# emac_reva register map
Registers are read-write, no defined reset value unless marked. A register's access mark holds for its fields unless they carry their own. Offsets are from the block's base; lines under a group give offsets from that group; [hi:lo] are bit positions; {n}, {i} and the like mark numbered series; 'fields as' and 'values as' point back to an identical list; <NAME> marks a mode.

## Memory map
0x4004F000 EMAC size 0x1000 — 10/100 Ethernet MAC.

## Interrupts
64 EMAC — EMAC IRQ

## EMAC — 10/100 Ethernet MAC.
Base 0x4004F000
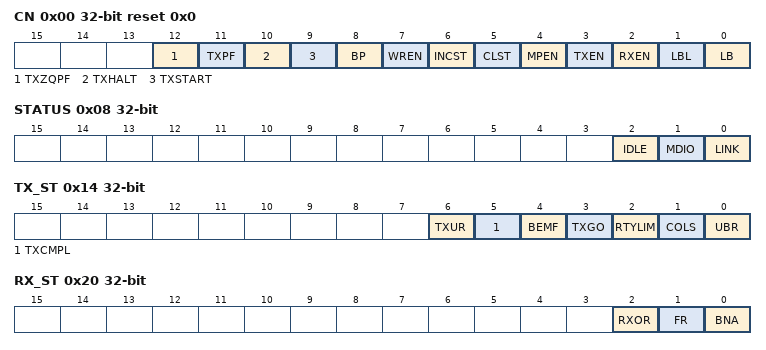
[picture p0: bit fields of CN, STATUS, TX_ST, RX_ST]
0x00 CN access per field reset 0x0 — Network Control Register.
  [12] TXZQPF wo — Transmit zero quantum pause frame.
  [11] TXPF wo — Transmit pause frame.
  [10] TXHALT wo — Transmit halt.
  [9] TXSTART wo — Transmission start.
  [8] BP rw — Back pressure.
  [7] WREN rw — Write enable for statistics registers.
  [6] INCST wo — Increment Statistics.
  [5] CLST wo — Clear Statistics.
  [4] MPEN rw — Management Port Enable.
  [3] TXEN rw — Transmit Enable.
  [2] RXEN rw — Receive Enable.
  [1] LBL rw — Loopback local.
  [0] LB rw — Loopback.
0x04 CFG access per field — Network Configuration Register.
  [19] IGNRXFCS wo — Ignore RX FCS. If 1, packets with FCS/CRC errors are not rejected and no FCS error statistics are counted. For normal operation, this bit must be set to 0.
  [18] HDPLXRXEN wo — Enable packets to be received in half-duplex mode while transmitting.
  [17] DCRXFCS wo — Discard receive FCS. If 1, the FCS field of received frames will not be copied to memory.
  [16] RXLFCEN wo — Receive length field checking enable. If 1, packets with measured lengths shorter than their length fields are discarded. Packets containing a type ID in bytes 13 and 14 (length/type field ≥0600) are not counted as length errors.
  [15:14] RXBUFFOFS wo — Receive buffer offset. These bits indicate the number of bytes by which the received data is offset from the start of the first receive buffer.
  [13] PAUSEEN wo — Pause Enable. If 1, Ethernet packet transmission pauses when a valid pause packet is received.
  [12] RTTST wo — Retry Test. Must be set to zero for normal operation. If set to 1, the back-off between collisions is always one slot time.
  [11] TXPF wo — Transmit pause frame.
  [11:10] MDCCLK wo — MDC Frequency. Set according to PCLK speed. This field determines by what number PCLK is divided to generate MDC.
    0=div8 (PCLK up to 20MHz); 1=div16 (PCLK up to 40MHz); 2=div32 (PCLK up to 80MHz); 3=div64 (PCLK up to 160MHz)
  [9] EAE rw
  [8] RXFR rw — Receive 1536 Byte Frames. Writing 1 to this bit means the MAC receives packets up to 1536 bytes in length. Normally the MAC rejects any packet above 1518 bytes
  [7] UHEN rw — Unicast Hash Enable. If 1, unicast frames will be received when the 6 bit hash function of the destination address points to a bit that is set in the hash register.
  [6] MHEN wo — Multicast Hash Enable. If 1, multicast frames will be received when the 6 bit hash function of the destination address points to a bit that is set in the hash register.
  [5] NOBC wo — No Broadcast. If 1, frames addressed to the broadcast address of all ones will not be received.
  [4] COPYAF rw — Copy All Frames. If 1, all valid frames will be received.
  [3] JUMBOFR rw — Jumbo Frames. Writing 1 to this bit enables jumbo frames of up to 10,240 bytes to be accepted.
  [2] BITRATE rw — Bit Rate. Writing 1 to this bit configures the interface for serial operation.
  [1] FULLDPLX rw — Full Duplex. If set to 1 the transmit block ignores the state of collision and carrier sense and allows Rx while transmitting.
  [0] SPD rw — Speed Select.
0x08 STATUS ro — Network Status Register.
  [2] IDLE rw — PHY management logic status.
  [1] MDIO rw — MDIO pin status. Returns status of the EMAC_MDIO pin. Use the PHY maintenance register for reading managed frames rather than this bit.
  [0] LINK rw — LINK pin status. Returns status of EMAC_LINK pin.
0x14 TX_ST — Transmit Status Register.
  [6] TXUR — Transmit Underrun. Set when the MAC transmit FIFO was read while was empty. If this happens the transmitter forces bad. Write 1 to clear this bit.
  [5] TXCMPL — Transmit Complete. Set when a frame has been transmitted. Write 1 to clear this bit.
  [4] BEMF — Buffers Exhausted Mid Frame. If the buffers run out during transmission of a frame then transmission stops, FCS shall be bad and EMAC_TXER asserted. Write 1 to clear this bit.
  [3] TXGO — Transmit Go. If 1, transmit is active.
  [2] RTYLIM — Retry Limit Exceeded. Set when the retry limit has been exceeded. Write 1 to clear this bit.
  [1] COLS — Collision Occurred. Set when a collision occurs. Write 1 to clear this bit.
  [0] UBR — Used Bit Read. Set when a transmit buffer descriptor is read with its used bit set. Write 1 to clear this bit.
0x18 RXBUF_PTR — Receive Buffer Queue Pointer Register.
  [31:2] RXBUF — Receive buffer queue pointer. Written with the address of the start of the receive queue, reads as a pointer to the current buffer being used.
0x1C TXBUF_PTR — Transmit Buffer Queue Pointer Register.
  [31:2] TXBUF — Transmit buffer queue pointer. Written with the address of the start of the transmit queue, reads as a pointer to the first buffer of the frame being transmitted or about to be transmitted.
0x20 RX_ST — Receive Status Register.
  [2] RXOR — Receive Overrun. The DMA block was unable to store the receive frame to memory. Either because the AHB bus was not granted in time or because a not OK hresp was returned. The buffer will be recovered if this happens. Write 1 to clear this bit.
  [1] FR — Frame Received. One or more frames have been received and placed in memory. Write 1 to clear this bit.
  [0] BNA — Buffer Not Available. An attempt was made to get a new buffer and the pointer indicated that it was owned by the processor. The DMA will reread the pointer each time a new frame starts until a valid pointer is found. This bit will be set at each attempt that fails even if it has not had a successful pointer read since it has been cleared. Write 1 to clear this bit.
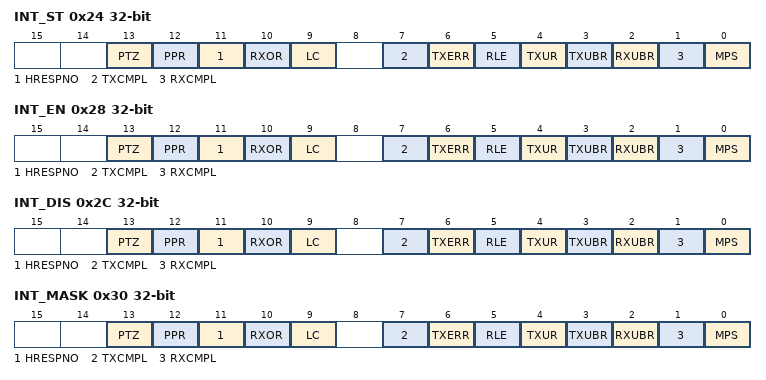
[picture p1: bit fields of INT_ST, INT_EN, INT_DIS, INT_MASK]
0x24 INT_ST — Interrupt Status Register.
  [13] PTZ — Pause Time Zero Interrupt Status. Set when the MAC Pause Time register (MAC_PT) decrements to zero. Cleared when read.
  [12] PPR — Pause Packet Received Interrupt Status. Indicates a valid pause packet has been received. Cleared when read.
  [11] HRESPNO — hresp not OK Interrupt Status. Set when the DMA block sees hresp not OK. Cleared when read.
  [10] RXOR — Receive Overrun Interrupt Status. Set when the receive overrun status bit gets set. Cleared when read.
  [9] LC — Link Change Interrupt Status. Set when the external link signal changes. Cleared when read.
  [7] TXCMPL — Transmit Complete Interrupt Status. Set when a frame has been transmitted. Cleared when read.
  [6] TXERR — Transmit Buffers Exhausted In Mid-frame Interrupt Status. Transmit error. Cleared when read.
  [5] RLE — Retry Limit Exceeded Interrupt Status. Transmit error. Cleared when read.
  [4] TXUR — Ethernet Transmit Underrun Interrupt Status. Set when the MAC transmit FIFO was read while was empty. If this happens the transmitter forces bad CRC and forces EMAC_TXER high. Cleared when read.
  [3] TXUBR — TX Used Bit Read Interrupt Status. Set when a transmit buffer descriptor is read with its used bit set. Cleared when read
  [2] RXUBR — RX Used Bit Read Interrupt Status. Set when a receive buffer descriptor is read with its used bit set. Cleared when read.
  [1] RXCMPL — Receive Complete Interrupt Status. Set when a frame has been stored in memory. Cleared when read.
  [0] MPS — Management Packet Sent Interrupt Status. The PHY maintenance register has completed its operation. Cleared when read.
0x28 INT_EN wo — Interrupt Enable Register.
  [13] PTZ rw — Pause Time Zero Interrupt Enable
  [12] PPR rw — Pause Packet Received Interrupt Enable
  [11] HRESPNO rw — hresp not OK Interrupt Enable
  [10] RXOR rw — Receive Overrun Interrupt Enable
  [9] LC rw — Link Change Interrupt Enable
  [7] TXCMPL rw — Transmit Complete Interrupt Enable
  [6] TXERR rw — Transmit Buffers Exhausted In Mid-frame Interrupt Enable
  [5] RLE rw — Retry Limit Exceeded Interrupt Enable
  [4] TXUR rw — Ethernet Transmit Underrun Interrupt Enable
  [3] TXUBR rw — TX Used Bit Read Interrupt Enable
  [2] RXUBR rw — RX Used Bit Read Interrupt Enable
  [1] RXCMPL rw — Receive Complete Interrupt Enable
  [0] MPS rw — Management Packet Sent Interrupt Enable
0x2C INT_DIS wo — Interrupt Disable Register.
  [13] PTZ rw — Pause Time Zero Interrupt Disable
  [12] PPR rw — Pause Packet Received Interrupt Disable
  [11] HRESPNO rw — hresp not OK Interrupt Disable
  [10] RXOR rw — Receive Overrun Interrupt Disable
  [9] LC rw — Link Change Interrupt Disable
  [7] TXCMPL rw — Transmit Complete Interrupt Disable
  [6] TXERR rw — Transmit Buffers Exhausted In Mid-frame Interrupt Disable
  [5] RLE rw — Retry Limit Exceeded Interrupt Disable
  [4] TXUR rw — Ethernet Transmit Underrun Interrupt Disable
  [3] TXUBR rw — TX Used Bit Read Interrupt Disable
  [2] RXUBR rw — RX Used Bit Read Interrupt Disable
  [1] RXCMPL rw — Receive Complete Interrupt Disable
  [0] MPS rw — Management Packet Sent Interrupt Disable
0x30 INT_MASK ro — Interrupt Mask Register.
  [13] PTZ rw — Pause Time Zero Interrupt Mask
  [12] PPR rw — Pause Packet Received Interrupt Mask
  [11] HRESPNO rw — hresp not OK Interrupt Mask
  [10] RXOR rw — Receive Overrun Interrupt Mask
  [9] LC rw — Link Change Interrupt Mask
  [7] TXCMPL rw — Transmit Complete Interrupt Mask
  [6] TXERR rw — Transmit Buffers Exhausted In Mid-frame Interrupt Mask
  [5] RLE rw — Retry Limit Exceeded Interrupt Mask
  [4] TXUR rw — Ethernet Transmit Underrun Interrupt Mask
  [3] TXUBR rw — TX Used Bit Read Interrupt Mask
  [2] RXUBR rw — RX Used Bit Read Interrupt Mask
  [1] RXCMPL rw — Receive Complete Interrupt Mask
  [0] MPS rw — Management Packet Sent Interrupt Mask
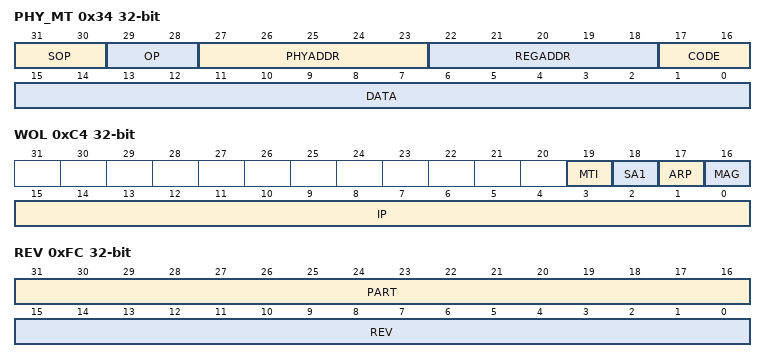
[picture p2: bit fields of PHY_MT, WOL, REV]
0x34 PHY_MT — PHY Maintenance Register.
  [31:30] SOP
  [29:28] OP — Operation
    1=write; 2=read
  [27:23] PHYADDR — PHY Address. Specifies the PHY to access.
  [22:18] REGADDR — Register Address. Specifies the register in the PHY to access.
  [17:16] CODE — Has to be 10b
  [15:0] DATA — PHY Data. For a write operation this field is the data to be written to the PHY.
0x38 PT ro — Pause Time Register.
  [15:0] TIME rw — Pause Time. Stores the current value of the pause time register, which is decremented every 512 bit times.
0x3C PFR — Pause Frame Received OK.
  [15:0] PFR — Pause Frames Received OK. A 16-bit register counting the number of good pause frames received.
0x40 FTOK — Frames Transmitted OK.
  [31:0] FTOK — Frames Transmitted OK. A 32-bit register counting the number of frames successfully transmitted, i.e. no underrun and not too many retries.
0x44 SCF — Single Collision Frames.
  [15:0] SCF — Single Collision Frames. A 16-bit register counting the number of frames experiencing a single collision before being successfully transmitted, i.e. no underrun.
0x48 MCF — Multiple Collision Frames.
  [15:0] MCF — Multiple Collision Frames. A 16-bit register counting the number of frames experiencing between two and fifteen collisions prior to being successfully transmitted, i.e. no underrun and not too many retries.
0x4C FROK — Fames Received OK.
  [23:0] FROK — Frames Received OK. A 24-bit register counting the number of good packets received
0x50 FCS_ERR — Frame Check Sequence Errors.
  [7:0] FCSERR
0x54 ALGN_ERR — Alignment Errors.
  [7:0] ALGNERR
0x58 DFTXF — Deferred Transmission Frames.
  [15:0] DFTXF — Deferred Transmission Frames. A 16-bit register counting the number of packets experiencing deferral due to carrier sense being active on their first attempt at transmission
0x5C LC — Late Collisions.
  [7:0] LC — Late Collisions. An 8-bit register counting the number of packets that experience a collision after the slot time (512 bits) has expired.
0x60 EC — Excessive Collisions.
  [7:0] EC — Excessive Collisions. An 8-bit register counting the number of packets that failed to be transmitted because they experienced 16 collisions.
0x64 TUR_ERR — Transmit Underrun Errors.
  [7:0] TURERR — Transmit Underrun Error. An 8-bit register counting the number of packets not transmitted due to a transmit FIFO underrun.
0x68 CS_ERR — Carrier Sense Errors.
  [7:0] CSERR — An 8-bit register counting the number of packets transmitted where carrier sense was not seen during transmission or where carrier sense was deasserted after being asserted in a transmit packet without collision (no underrun).
0x6C RR_ERR — Receive Resource Errors.
  [15:0] RRERR — Receive Resource Errors. A 16 bit register counting the number of frames that were address matched but could not be copied to memory because no receive buffer was available.
0x70 ROR_ERR — Receive Overrun Errors.
  [7:0] RORERR — Receive Overruns. An 8 bit register counting the number of frames that are address recognized but were not copied to memory due to a receive DMA overrun.
0x74 RS_ERR — Receive Symbol Errors.
  [7:0] RSERR — Receive Symbol Errors. An 8-bit register counting the number of packets that had EMAC_RXER asserted during reception.
0x78 EL_ERR — Excessive Length Errors.
  [7:0] ELERR — Excessive Length Errors. An 8-bit register counting the number of packets received exceeding 1518 bytes in length (1536 if RXFR is set in the MAC_CFG register;
0x7C RJ — Receive Jabber.
  [7:0] RJERR — Receive Jabbers. An 8-bit register counting the number of packets received exceeding 1518 bytes in length (1536 if RXFR is set in the MAC_CFG register;
0x80 USF — Undersize Frames.
  [7:0] USF — Undersize Frames. An 8-bit register counting the number of packets received less than 64 bytes in length but do not have either a CRC error, an alignment error or a receive symbol error.
0x84 SQE_ERR — SQE Test Errors.
  [7:0] SQEERR — SQE Test Errors. An 8-bit register counting the number of packets where collision was not asserted within 96 bit times (an interframe gap) of EMAC_TXEN being deasserted in half duplex mode.
0x88 RLFM — Received Length Field Mismatch.
  [7:0] RLFM — Receive length field mismatch
0x8C TPF — Transmitted Pause Frames.
  [15:0] TPF — Transmitted Pause Frames. A 16-bit register counting the number of pause packets transmitted.
0x90 HASHL — Hash Register Bottom [31:0].
  [31:0] HASH — Bits 31:0 of the hash address register. See Hash Addressing
0x94 HASHH — Hash Register top [63:32].
  [31:0] HASH — Bits 63:32 of the hash address register. See Hash Addressing
{0x90+8i} SA{i}L (i=1..4) — Specific Address {i} Bottom.
  [31:0] ADDR — MAC Specific Address {i} [31:0]. Least significant bits of the MAC specific address {i}, i.e. bits 31:0. This field is used for transmission of pause packets
{0x94+8i} SA{i}H (i=1..4) — Specific Address {i} Top.
  [15:0] ADDR — MAC Specific Address {i} [47:32]. Most significant bits of the MAC specific address {i}, i.e. bits 47:32.
0xB8 TID_CK — Type ID Checking.
  [15:0] TID — Type ID Checking. For use in comparisons with received frames TypeID/Length field.
0xBC TPQ — Transmit Pause Quantum.
  [15:0] TPQ — Transmit Pause Quantum. Used in hardware generation of transmitted pause packets as value for pause quantum
0xC0 USRIO — User Input Output Register
  [0] MII
0xC4 WOL — Wake On LAN Register
  [19] MTI, [18] SA1, [17] ARP, [16] MAG, [15:0] IP
0xFC REV ro — Revision register.
  [31:16] PART rw — Part Reference. For Ethernet MAC design, this is fixed at 0x01.
  [15:0] REV rw — Revision Reference. Fixed two byte value specific to revision of design.
